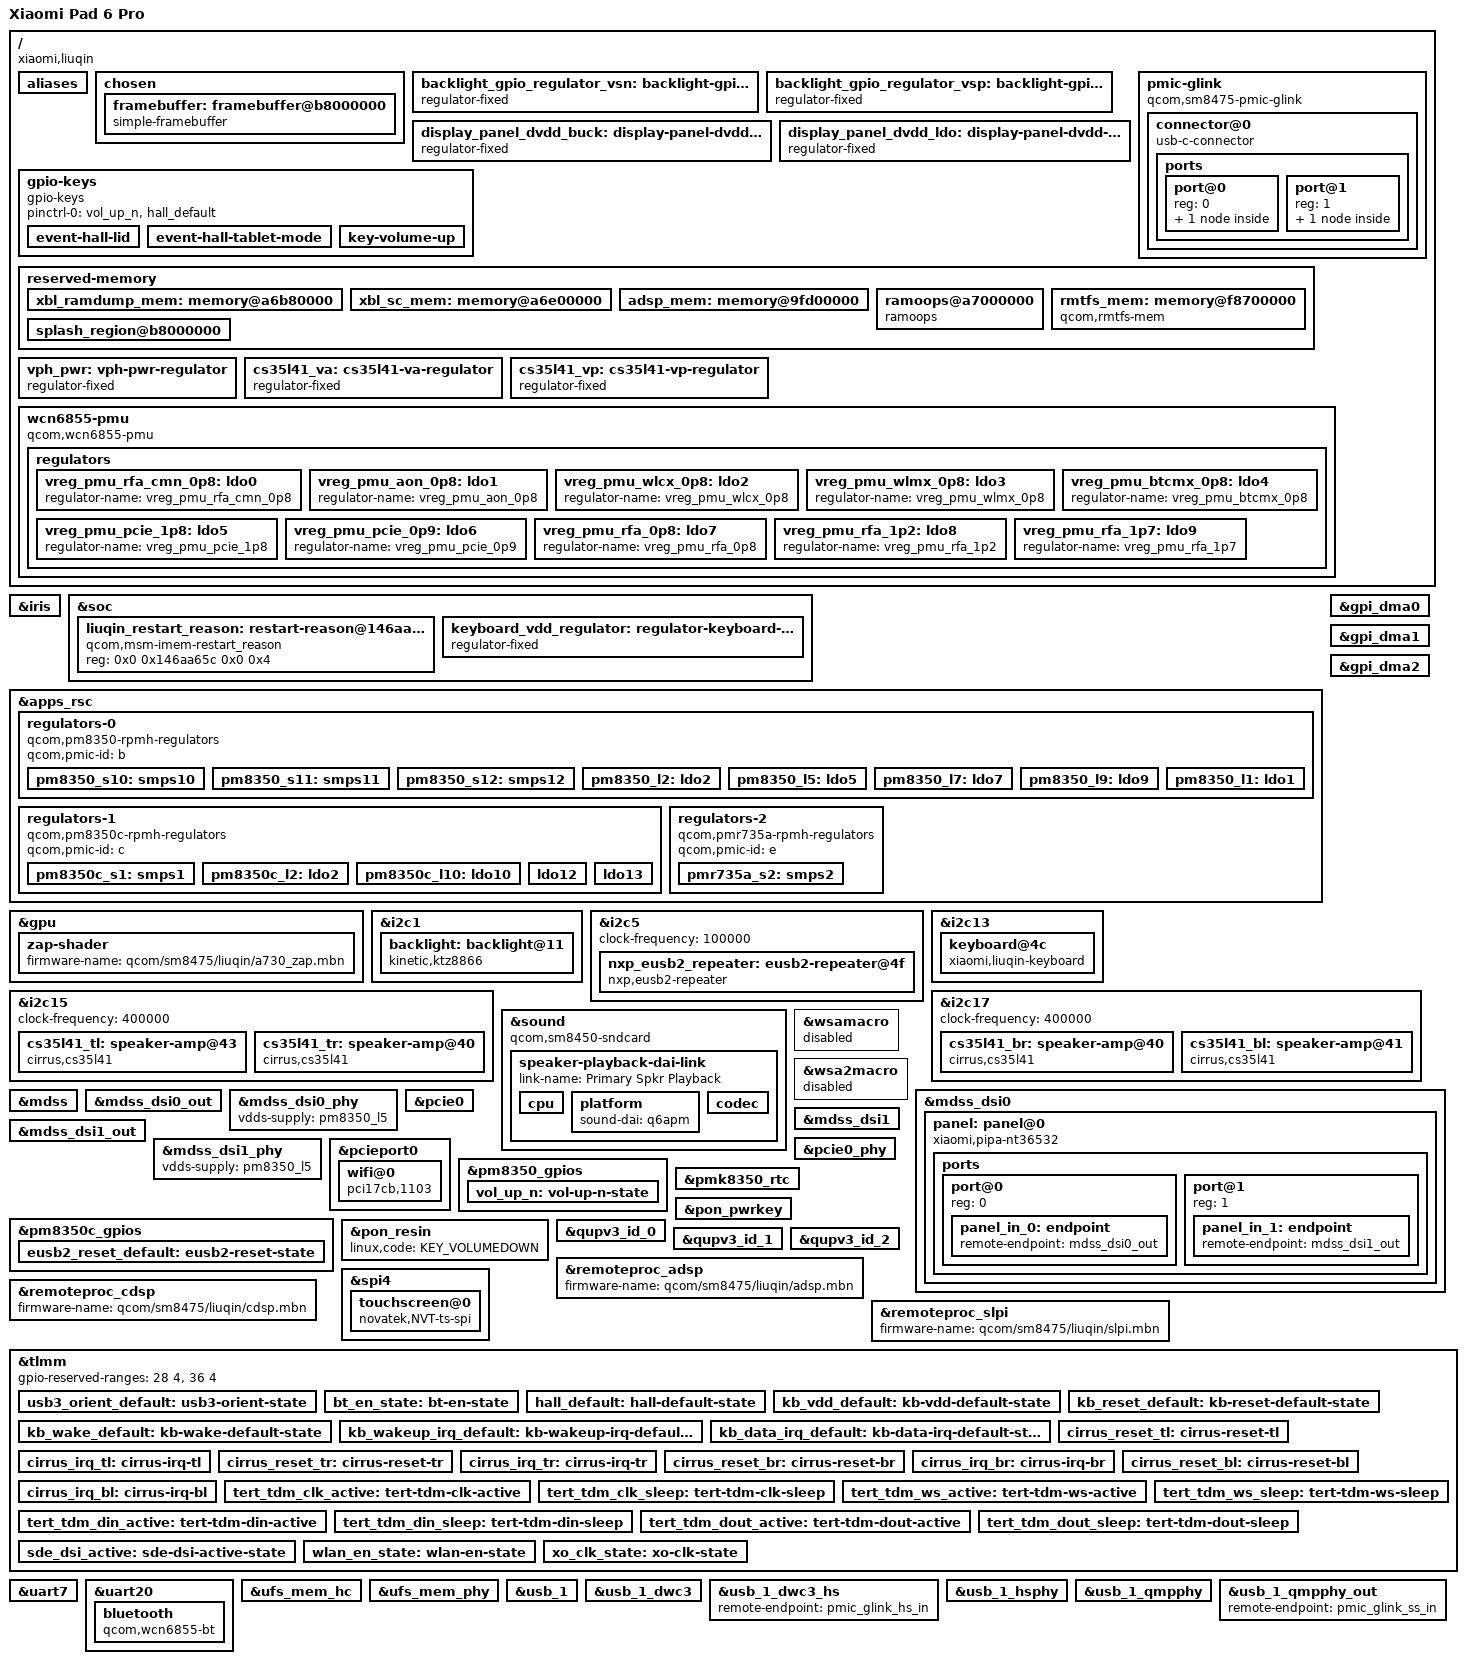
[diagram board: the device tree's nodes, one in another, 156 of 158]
// SPDX-License-Identifier: GPL-2.0-only
/dts-v1/;

#include <dt-bindings/input/input.h>
#include <dt-bindings/interrupt-controller/irq.h>
#include <dt-bindings/pinctrl/qcom,pmic-gpio.h>
#include <dt-bindings/regulator/qcom,rpmh-regulator.h>

#include "sm8475.dtsi"
#include "pm8350.dtsi"
#include "pm8350b.dtsi"
#include "pm8350c.dtsi"
#include "pm8450.dtsi"
#include "pmk8350.dtsi"
#include "pmr735a.dtsi"

/* The firmware memory map differs from the generic SM8450 layout. */
/delete-node/ &adsp_mem;
/delete-node/ &rmtfs_mem;
/delete-node/ &xbl_ramdump_mem;
/delete-node/ &xbl_sc_mem;

/ {
	model = "Xiaomi Pad 6 Pro";
	compatible = "xiaomi,liuqin", "qcom,sm8475";
	chassis-type = "tablet";

	aliases {
		hsuart0 = &uart20;
		serial0 = &uart7;
	};

	chosen {
		#address-cells = <2>;
		#size-cells = <2>;
		ranges;

		stdout-path = "serial0:115200n8";
		/*
		 * The bootloader appends its own command line to this property
		 * rather than replacing it, so the kernel only ever sees what is
		 * written here. Keep it in sync with the boot image header.
		 *
		 * The panel is the only channel on a retail tablet. earlycon=simplefb
		 * draws onto the framebuffer below from parse_early_param(), which is
		 * the only way to see a failure earlier than device_initcall, where
		 * the DRM log client can take over. Four parts are load-bearing and
		 * each one
		 * silently loses that window on its own:
		 *
		 *   earlycon=simplefb   - a bare "earlycon" never reaches the DT,
		 *                         CONFIG_ACPI_SPCR_TABLE claims it first.
		 *   keep_bootcon        - console_init() runs before every initcall
		 *                         and registers the VT console as CON_CONSDEV,
		 *                         at which point printk unregisters every
		 *                         CON_BOOT console unless this is set.
		 *   console=drm_log     - enables the late-registering DRM console;
		 *                         its first write is what commits the initial
		 *                         atomic modeset. console=tty0 follows it so
		 *                         /dev/console remains the VT for userspace.
		 *   initcall_blacklist= - stops simplefb binding, so fbcon never takes
		 *     simplefb_driver_init  the same framebuffer and the two consoles
		 *                         do not draw over each other. Costs nothing:
		 *                         if the boot gets that far we have USB.
		 * stdout-path is not used by either console -- it names the GENI debug
		 * UART, which is not brought out on a retail unit.
		 */
		bootargs = "earlycon=simplefb keep_bootcon console=drm_log console=tty0 initcall_blacklist=simplefb_driver_init initcall_debug ignore_loglevel clk_ignore_unused pd_ignore_unused rootwait mtdoops.dump_oops=1 hung_task_panic=1 softlockup_panic=1 panic=15";

		framebuffer: framebuffer@b8000000 {
			compatible = "simple-framebuffer";
			reg = <0x0 0xb8000000 0x0 0x2b00000>;
			width = <1800>;
			height = <2880>;
			stride = <(1800 * 4)>;
			format = "a8r8g8b8";

			clocks = <&gcc GCC_DISP_HF_AXI_CLK>;
		};
	};

	/*
	 * The panel and its backlight run off five rails. One is a PMIC LDO
	 * (iovdd, pm8350c_l2, wired at &mdss_dsi0/panel@0 below); the other four
	 * are load switches the SoC gates directly, which the vendor tree models
	 * as regulator-fixed with a TLMM gpio -- and so does this, node for node,
	 * following the stock device tree supplied by the bootloader:
	 *
	 *   display_gpio_regulator_dvdd_buck  :33115  gpio 2   1.3 V
	 *   display_gpio_regulator_dvdd_ldo   :33126  gpio 93  1.3 V
	 *   display_gpio_regulator_vsp        :33137  gpio 66  5.5 V, ramp 233 us
	 *   display_gpio_regulator_vsn        :33149  gpio 53  5.5 V, ramp 233 us
	 *
	 * vsp/vsn are not panel rails in the usual sense: gpio 66 and gpio 53 are
	 * the KTZ8866's own ENP and ENN pins (:12676-12677), i.e. the enables for
	 * its positive and negative LCD bias outputs. That is why they are
	 * consumed by backlight@11 as vddpos/vddneg rather than by the panel.
	 *
	 * regulator-always-on throughout, as on yudi: nothing here can be
	 * sequenced off safely while the bootloader's splash is still scanning
	 * out, and the panel driver's unprepare path would otherwise drop rails
	 * the earlycon framebuffer still depends on.
	 */
	backlight_gpio_regulator_vsn: backlight-gpio-reg-vsn {
		compatible = "regulator-fixed";
		regulator-name = "backlight_gpio_vsn";
		regulator-min-microvolt = <5500000>;
		regulator-max-microvolt = <5500000>;
		regulator-enable-ramp-delay = <233>;
		gpio = <&tlmm 53 GPIO_ACTIVE_HIGH>;
		enable-active-high;
		regulator-boot-on;
		regulator-always-on;
	};

	backlight_gpio_regulator_vsp: backlight-gpio-reg-vsp {
		compatible = "regulator-fixed";
		regulator-name = "backlight_gpio_vsp";
		regulator-min-microvolt = <5500000>;
		regulator-max-microvolt = <5500000>;
		regulator-enable-ramp-delay = <233>;
		gpio = <&tlmm 66 GPIO_ACTIVE_HIGH>;
		enable-active-high;
		regulator-boot-on;
		regulator-always-on;
	};

	display_panel_dvdd_buck: display-panel-dvdd-buck {
		compatible = "regulator-fixed";
		regulator-name = "display_panel_dvdd_buck";
		regulator-min-microvolt = <1300000>;
		regulator-max-microvolt = <1300000>;
		gpio = <&tlmm 2 GPIO_ACTIVE_HIGH>;
		enable-active-high;
		regulator-boot-on;
		regulator-always-on;
	};

	display_panel_dvdd_ldo: display-panel-dvdd-ldo {
		compatible = "regulator-fixed";
		regulator-name = "display_panel_dvdd_ldo";
		regulator-min-microvolt = <1300000>;
		regulator-max-microvolt = <1300000>;
		gpio = <&tlmm 93 GPIO_ACTIVE_HIGH>;
		enable-active-high;
		regulator-boot-on;
		regulator-always-on;
	};

	gpio-keys {
		compatible = "gpio-keys";

		pinctrl-0 = <&vol_up_n>, <&hall_default>;
		pinctrl-names = "default";

		/*
		 * Two hall switches, plain TLMM GPIOs (vendor hall_key/hall_key1,
		 * abl-final-fdt.dts gpio_keys): gpio10 closes with the folio lid,
		 * gpio23 signals tablet-mode.  SW_LID lets logind blank on close;
		 * SW_TABLET_MODE drives GNOME's on-screen-keyboard decision.  The
		 * nanosic keyboard MCU reads the same magnets separately; these
		 * switches do not depend on it.
		 */
		event-hall-lid {
			label = "Hall Lid";
			linux,input-type = <EV_SW>;
			linux,code = <SW_LID>;
			gpios = <&tlmm 10 GPIO_ACTIVE_LOW>;
			debounce-interval = <150>;
			wakeup-source;
		};

		event-hall-tablet-mode {
			label = "Hall Tablet Mode";
			linux,input-type = <EV_SW>;
			linux,code = <SW_TABLET_MODE>;
			/*
			 * GNOME semantics: SW_TABLET_MODE=1 means "no keyboard attached".
			 * This hall pin is pulled up when no magnet (keyboard/folio) is
			 * near, so active-high maps detached -> tablet mode and attached
			 * -> laptop mode -- the latter additionally gates GNOME's
			 * on-screen keyboard.
			 */
			gpios = <&tlmm 23 GPIO_ACTIVE_HIGH>;
			debounce-interval = <150>;
			wakeup-source;
		};

		key-volume-up {
			label = "Volume Up";
			linux,code = <KEY_VOLUMEUP>;
			gpios = <&pm8350_gpios 6 GPIO_ACTIVE_LOW>;
			debounce-interval = <15>;
			linux,can-disable;
			wakeup-source;
		};
	};

	/*
	 * The charger PD runs on ADSP and publishes PMIC_RTR_ADSP_APPS, exactly
	 * as the vendor FDT describes.  The connector is now wired through as
	 * well: pmic-glink UCSI reports the data role and CC orientation, the
	 * DWC3 follows it as an OTG dual-role port, and the QMP combo PHY takes
	 * the orientation for its lane swap (vendor routes the CC orientation
	 * line to TLMM gpio91).
	 */
	pmic-glink {
		compatible = "qcom,sm8475-pmic-glink",
			     "qcom,sm8450-pmic-glink",
			     "qcom,pmic-glink";
		#address-cells = <1>;
		#size-cells = <0>;

		orientation-gpios = <&tlmm 91 GPIO_ACTIVE_HIGH>;
		pinctrl-0 = <&usb3_orient_default>;
		pinctrl-names = "default";

		connector@0 {
			compatible = "usb-c-connector";
			reg = <0>;
			power-role = "dual";
			data-role = "dual";

			ports {
				#address-cells = <1>;
				#size-cells = <0>;

				port@0 {
					reg = <0>;

					pmic_glink_hs_in: endpoint {
						remote-endpoint = <&usb_1_dwc3_hs>;
					};
				};

				port@1 {
					reg = <1>;

					pmic_glink_ss_in: endpoint {
						remote-endpoint = <&usb_1_qmpphy_out>;
					};
				};
			};
		};
	};

	reserved-memory {
		xbl_ramdump_mem: memory@a6b80000 {
			reg = <0x0 0xa6b80000 0x0 0x280000>;
			no-map;
		};

		xbl_sc_mem: memory@a6e00000 {
			reg = <0x0 0xa6e00000 0x0 0x40000>;
			no-map;
		};

		adsp_mem: memory@9fd00000 {
			reg = <0x0 0x9fd00000 0x0 0x3100000>;
			no-map;
		};

		/*
		 * Zone sizes deliberately match the vendor firmware's own ramoops
		 * node, so the console zone lands at the same physical address and
		 * length in both kernels. That makes a failed boot here readable
		 * from the stock kernel's /sys/fs/pstore afterwards, which is the
		 * only post-mortem channel this board has: the debug UART is not
		 * accessible on a retail unit. pstore allocates dmesg, console then
		 * pmsg in that order, so any extra dmesg record zone would shift
		 * the console zone and break that compatibility.
		 */
		ramoops@a7000000 {
			compatible = "ramoops";
			reg = <0x0 0xa7000000 0x0 0x400000>;
			console-size = <0x200000>;
			pmsg-size = <0x200000>;
			no-map;
		};

		rmtfs_mem: memory@f8700000 {
			compatible = "qcom,rmtfs-mem";
			reg = <0x0 0xf8700000 0x0 0x280000>;
			no-map;

			qcom,client-id = <1>;
			qcom,vmid = <QCOM_SCM_VMID_MSS_MSA>;
		};

		splash_region@b8000000 {
			reg = <0x0 0xb8000000 0x0 0x2b00000>;
			no-map;
		};
	};

	vph_pwr: vph-pwr-regulator {
		compatible = "regulator-fixed";
		regulator-name = "vph_pwr";
		regulator-min-microvolt = <3700000>;
		regulator-max-microvolt = <3700000>;
		regulator-always-on;
		regulator-boot-on;
	};

	/*
	 * The four CS35L41 speaker amps have no VA-supply / VP-supply in the
	 * vendor tree the bootloader hands over (abl-final-fdt.dts:13410-13620).
	 * The rails are hard-wired. Mainline cs35l41_probe() still does a
	 * regulator_bulk_get() for "VA" and "VP" and will not probe without
	 * them; these always-on placeholders exist only to satisfy that API.
	 * They have no GPIO and do not gate hardware. Voltages are the
	 * datasheet-typical analog / battery rails, not a measured PMIC LDO.
	 */
	cs35l41_va: cs35l41-va-regulator {
		compatible = "regulator-fixed";
		regulator-name = "cs35l41_va";
		regulator-min-microvolt = <1800000>;
		regulator-max-microvolt = <1800000>;
		regulator-always-on;
		regulator-boot-on;
	};

	cs35l41_vp: cs35l41-vp-regulator {
		compatible = "regulator-fixed";
		regulator-name = "cs35l41_vp";
		regulator-min-microvolt = <3700000>;
		regulator-max-microvolt = <3700000>;
		regulator-always-on;
		regulator-boot-on;
	};

	/*
	 * Power sequencer for the QCA6490 combo chip. It owns the enable
	 * lines and the shared rails for both radios, so it has to exist
	 * before either the Bluetooth UART child below or a future WLAN
	 * endpoint on PCIe RC0 can be powered.
	 *
	 * GPIOs and supplies follow the stock device tree supplied by the
	 * bootloader to the vendor kernel.
	 * The vendor splits the same hardware across two nodes -- bt_qca6490
	 * at :1310 and qcom,cnss-qca6490 at :12525 -- which agree on every
	 * line: wlan-en gpio80 (0x50), bt-en gpio81 (0x51), sw-ctrl gpio82
	 * (0x52) and xo-clk gpio204 (0xcc), all against phandle 0x3c, which
	 * is pinctrl@f000000, i.e. TLMM (:1367).
	 */
	wcn6855-pmu {
		compatible = "qcom,wcn6855-pmu";

		pinctrl-0 = <&bt_en_state>, <&wlan_en_state>, <&xo_clk_state>;
		pinctrl-names = "default";

		wlan-enable-gpios = <&tlmm 80 GPIO_ACTIVE_HIGH>;
		bt-enable-gpios = <&tlmm 81 GPIO_ACTIVE_HIGH>;
		swctrl-gpios = <&tlmm 82 GPIO_ACTIVE_HIGH>;
		xo-clk-gpios = <&tlmm 204 GPIO_ACTIVE_HIGH>;

		vddio-supply = <&pm8350_s10>;
		vddaon-supply = <&pmr735a_s2>;
		vddpmu-supply = <&pm8350_s11>;
		vddpmumx-supply = <&pmr735a_s2>;
		vddpmucx-supply = <&pm8350_s11>;
		vddrfa0p95-supply = <&pm8350_s11>;
		vddrfa1p3-supply = <&pm8350_s12>;
		vddrfa1p9-supply = <&pm8350c_s1>;
		vddpcie1p3-supply = <&pm8350_s12>;
		vddpcie1p9-supply = <&pm8350c_s1>;

		regulators {
			vreg_pmu_rfa_cmn_0p8: ldo0 {
				regulator-name = "vreg_pmu_rfa_cmn_0p8";
			};

			vreg_pmu_aon_0p8: ldo1 {
				regulator-name = "vreg_pmu_aon_0p8";
			};

			vreg_pmu_wlcx_0p8: ldo2 {
				regulator-name = "vreg_pmu_wlcx_0p8";
			};

			vreg_pmu_wlmx_0p8: ldo3 {
				regulator-name = "vreg_pmu_wlmx_0p8";
			};

			vreg_pmu_btcmx_0p8: ldo4 {
				regulator-name = "vreg_pmu_btcmx_0p8";
			};

			vreg_pmu_pcie_1p8: ldo5 {
				regulator-name = "vreg_pmu_pcie_1p8";
			};

			vreg_pmu_pcie_0p9: ldo6 {
				regulator-name = "vreg_pmu_pcie_0p9";
			};

			vreg_pmu_rfa_0p8: ldo7 {
				regulator-name = "vreg_pmu_rfa_0p8";
			};

			vreg_pmu_rfa_1p2: ldo8 {
				regulator-name = "vreg_pmu_rfa_1p2";
			};

			vreg_pmu_rfa_1p7: ldo9 {
				regulator-name = "vreg_pmu_rfa_1p7";
			};
		};
	};
};

&iris {
	status = "okay";
};

/*
 * Power to the magnetic keyboard's pogo pins, gated by the vendor's vdd_pin
 * (abl-final-fdt.dts:13288). Nothing describes its voltage: the vendor tree
 * carries a bare GPIO with no rail behind it, and the bridge chip's supply is
 * generated on the folio side. startup-delay-us preserves the vendor's 2 ms
 * rail-to-reset delay.
 *
 * Keep the provider under the real simple-bus. ABL applies the vendor dtbo
 * after the boot image DTB and has already been observed rewriting or dropping
 * root-level additions, while children of /soc@0 survive in the live FDT.
 */
&soc {
	/*
	 * Xiaomi ABL consumes the Android restart reason at IMEM + 0x65c.
	 * The vendor FDT exposes the same 4-byte window below its msm-imem
	 * container; a direct /soc@0 child survives ABL's later overlay while
	 * root-level additions do not.
	 */
	liuqin_restart_reason: restart-reason@146aa65c {
		compatible = "qcom,msm-imem-restart_reason";
		reg = <0x0 0x146aa65c 0x0 0x4>;
	};

	keyboard_vdd_regulator: regulator-keyboard-vdd {
		compatible = "regulator-fixed";
		regulator-name = "keyboard_vdd";

		gpio = <&tlmm 62 GPIO_ACTIVE_HIGH>;
		enable-active-high;
		startup-delay-us = <2000>;

		pinctrl-0 = <&kb_vdd_default>;
		pinctrl-names = "default";
	};
};

&apps_rsc {
	regulators-0 {
		compatible = "qcom,pm8350-rpmh-regulators";
		qcom,pmic-id = "b";

		pm8350_s10: smps10 {
			regulator-name = "pm8350_s10";
			regulator-min-microvolt = <1800000>;
			regulator-max-microvolt = <1800000>;
		};

		pm8350_s11: smps11 {
			regulator-name = "pm8350_s11";
			regulator-min-microvolt = <382000>;
			regulator-max-microvolt = <1170000>;
		};

		pm8350_s12: smps12 {
			regulator-name = "pm8350_s12";
			regulator-min-microvolt = <1224000>;
			regulator-max-microvolt = <2040000>;
		};

		pm8350_l2: ldo2 {
			regulator-name = "pm8350_l2";
			regulator-min-microvolt = <2700000>;
			regulator-max-microvolt = <3300000>;
			regulator-initial-mode = <RPMH_REGULATOR_MODE_HPM>;
		};

		pm8350_l5: ldo5 {
			regulator-name = "pm8350_l5";
			regulator-min-microvolt = <720000>;
			regulator-max-microvolt = <958000>;
			regulator-initial-mode = <RPMH_REGULATOR_MODE_HPM>;
		};

		pm8350_l7: ldo7 {
			regulator-name = "pm8350_l7";
			regulator-min-microvolt = <2400000>;
			regulator-max-microvolt = <3544000>;
			regulator-initial-mode = <RPMH_REGULATOR_MODE_HPM>;
		};

		pm8350_l9: ldo9 {
			regulator-name = "pm8350_l9";
			regulator-min-microvolt = <1200000>;
			regulator-max-microvolt = <1304000>;
			regulator-initial-mode = <RPMH_REGULATOR_MODE_HPM>;
		};

		/*
		 * USB3 QMP combo PHY PLL rail. The vendor names L1B as the
		 * ssphy vdd-supply at 0.912 V (vendor FDT usb_qmp_dp_phy).
		 */
		pm8350_l1: ldo1 {
			regulator-name = "pm8350_l1";
			regulator-min-microvolt = <912000>;
			regulator-max-microvolt = <912000>;
			regulator-initial-mode = <RPMH_REGULATOR_MODE_HPM>;
		};
	};

	regulators-1 {
		compatible = "qcom,pm8350c-rpmh-regulators";
		qcom,pmic-id = "c";

		pm8350c_s1: smps1 {
			regulator-name = "pm8350c_s1";
			regulator-min-microvolt = <1800000>;
			regulator-max-microvolt = <2024000>;
			regulator-always-on;
		};

		/*
		 * The panel's iovdd. Range copied from the vendor's own
		 * regulator-pm8350c-l2 (abl-final-fdt.dts:6179-6187,
		 * phandle 0x301), which qcom,dsi-display-primary names as
		 * iovdd-supply at :32975.
		 */
		pm8350c_l2: ldo2 {
			regulator-name = "pm8350c_l2";
			regulator-min-microvolt = <1800000>;
			regulator-max-microvolt = <1980000>;
			regulator-initial-mode = <RPMH_REGULATOR_MODE_HPM>;
		};

		pm8350c_l10: ldo10 {
			regulator-name = "pm8350c_l10";
			regulator-min-microvolt = <1200000>;
			regulator-max-microvolt = <1304000>;
			regulator-initial-mode = <RPMH_REGULATOR_MODE_HPM>;
		};

		ldo12 {
			regulator-name = "pm8350c_l12";
			regulator-min-microvolt = <1800000>;
			regulator-max-microvolt = <1800000>;
			regulator-initial-mode = <RPMH_REGULATOR_MODE_HPM>;
			regulator-boot-on;
			regulator-always-on;
		};

		ldo13 {
			regulator-name = "pm8350c_l13";
			regulator-min-microvolt = <3304000>;
			regulator-max-microvolt = <3304000>;
			regulator-initial-mode = <RPMH_REGULATOR_MODE_HPM>;
			regulator-boot-on;
			regulator-always-on;
		};
	};

	regulators-2 {
		compatible = "qcom,pmr735a-rpmh-regulators";
		qcom,pmic-id = "e";

		pmr735a_s2: smps2 {
			regulator-name = "pmr735a_s2";
			regulator-min-microvolt = <500000>;
			regulator-max-microvolt = <1040000>;
			regulator-always-on;
		};
	};
};

&gpi_dma0 {
	status = "okay";
};

&gpi_dma1 {
	status = "okay";
};

&gpi_dma2 {
	status = "okay";
};

&gpu {
	status = "okay";

	zap-shader {
		firmware-name = "qcom/sm8475/liuqin/a730_zap.mbn";
	};
};

/*
 * The backlight is a Kinetic KTZ8866 at address 0x11 on QUPv3 wrapper 0's
 * second serial engine -- the vendor's i2c@984000 (abl-final-fdt.dts:12657),
 * which is what sm8450.dtsi:1364 calls i2c1. Address, enable line and the
 * ENP/ENN rails all come from the vendor's ktz8866@11 (:12674-12681).
 *
 * No clock-frequency: sm8450.dtsi does not set one, so i2c-qcom-geni falls
 * back to 100 kHz, which is what yudi runs this same chip on this same bus at.
 * The vendor node does not specify one either.
 */
&i2c1 {
	status = "okay";

	/*
	 * "kinetic,ktz8866", not ktz8866a. The fork's driver keys a two-chip
	 * interlock off the compatible: ktz8866a is driver_data 1 and
	 * ktz8866_probe() returns -EPROBE_DEFER for as long as no ktz8866b has
	 * registered (drivers/video/backlight/ktz8866.c:147). That pairing is a
	 * 14" yudi thing -- it carries two of these, on i2c1 and i2c5. This
	 * unit has exactly one (abl-final-fdt.dts:12674), so anything but the
	 * plain compatible would defer forever, and the panel, which waits on
	 * this device through drm_panel_of_backlight(), would defer with it.
	 *
	 * current-num-sinks = 5 follows sm8250-xiaomi-pipa.dts:519 and
	 * sm8250-xiaomi-elish-common.dtsi:585 rather than yudi: the vendor tree
	 * specifies no sink count at all, and pipa is the same 11" panel
	 * generation. Enabling a sink with no string on it is what the driver
	 * would do by default (all six, ktz8866.c:110-113).
	 */
	backlight: backlight@11 {
		compatible = "kinetic,ktz8866";
		reg = <0x11>;

		vddpos-supply = <&backlight_gpio_regulator_vsp>;
		vddneg-supply = <&backlight_gpio_regulator_vsn>;

		enable-gpios = <&tlmm 6 GPIO_ACTIVE_HIGH>;

		current-num-sinks = <5>;
		kinetic,current-ramp-delay-ms = <128>;
		kinetic,led-enable-ramp-delay-ms = <1>;
		kinetic,enable-lcd-bias;
	};
};

&i2c5 {
	clock-frequency = <100000>;
	status = "okay";

	nxp_eusb2_repeater: eusb2-repeater@4f {
		compatible = "nxp,eusb2-repeater";
		reg = <0x4f>;
		vdd18-supply = <&pm8350_s10>;
		vdd3-supply = <&pm8350_l2>;
		reset-gpios = <&pm8350c_gpios 7 GPIO_ACTIVE_HIGH>;
		pinctrl-0 = <&eusb2_reset_default>;
		pinctrl-names = "default";
		#phy-cells = <0>;

		qcom,param-override-seq = <0x40 0x06 0x00 0x07
					     0x63 0x08 0x03 0x0a>;
		qcom,param-override-seq-host = <0x40 0x06 0x21 0x07
						  0x64 0x08 0x03 0x0a>;
	};
};

/*
 * The magnetic keyboard folio's bridge chip, a Nanosic WN8030. The vendor tree
 * has it as nanosic@4c under i2c@a94000 (abl-final-fdt.dts:13263-13293), which
 * is sm8450.dtsi's i2c13 -- QUPv3 wrapper 1, SE 5. The pin state that .dtsi
 * already selects for it, qup_i2c13_data_clk, is gpio48/gpio49 at drive 2 with
 * a pull-up, matching the vendor's qupv3_se13_i2c_active (:3438) word for word.
 *
 * No clock-frequency, for the same reason as the amplifiers below: the vendor
 * node sets none, so the bus runs at i2c-qcom-geni's 100 kHz default.
 */
&i2c13 {
	status = "okay";

	keyboard@4c {
		compatible = "xiaomi,liuqin-keyboard", "nanosic,wn8030";
		reg = <0x4c>;

		/*
		 * Two lines out of the bridge:
		 *
		 *  "data"   gpio50. The vendor passes this pin's third DT cell,
		 *           0x6001, straight to request_threaded_irq() as flags
		 *           (nano_driver.c:67 -> nano_i2c.c:543), where it reads
		 *           as NO_SUSPEND | ONESHOT | TRIGGER_RISING. Rising is
		 *           what matters here; the source comment nearby claims
		 *           falling and is simply wrong.
		 *  "wakeup" gpio46, the vendor's status_pin: a rising edge while
		 *           the system is suspended. The I2C core claims this named
		 *           dedicated wake IRQ; hid-nanosic owns only the data IRQ.
		 */
		interrupts-extended = <&tlmm 50 IRQ_TYPE_EDGE_RISING>,
				      <&tlmm 46 IRQ_TYPE_EDGE_RISING>;
		interrupt-names = "data", "wakeup";

		vdd-supply = <&keyboard_vdd_regulator>;

		/* reset_pin gpio83, asserted low. */
		reset-gpios = <&tlmm 83 GPIO_ACTIVE_LOW>;

		/*
		 * sleep_pin gpio42: high keeps the bridge running, low lets it
		 * sleep. Named for what the line does, because the vendor's own
		 * Nanosic_GPIO_sleep(true) means wake up, not sleep.
		 */
		wake-gpios = <&tlmm 42 GPIO_ACTIVE_HIGH>;

		pinctrl-0 = <&kb_data_irq_default>, <&kb_wakeup_irq_default>,
			    <&kb_reset_default>, <&kb_wake_default>;
		pinctrl-names = "default";

		wakeup-source;

		/*
		 * Deliberately no hall-*-gpios. The vendor node lists
		 * hall_n_pin gpio10 and hall_s_pin gpio23, but those two are
		 * already claimed above as gpio-keys SW_LID / SW_TABLET_MODE,
		 * which is what logind and GNOME consume. A second consumer
		 * would take this node's probe down with -EBUSY, and would gain
		 * nothing: the vendor driver only forwarded those levels to a
		 * Xiaomi userspace daemon that does not exist here.
		 */
	};
};

/*
 * Speaker amplifiers. Four Cirrus CS35L41 parts, two per I2C controller, from
 * the tree the bootloader actually handed the vendor kernel:
 *
 *   i2c@880000 (sm8450.dtsi i2c15)  abl-final-fdt.dts:13393
 *     @43 TL  reset gpio1   irq gpio88   :13410-13433
 *     @40 TR  reset gpio3   irq gpio63   :13435-13458
 *   i2c@888000 (sm8450.dtsi i2c17)  :13556
 *     @40 BR  reset gpio92  irq gpio89   :13572-13595
 *     @41 BL  reset gpio87  irq gpio90   :13597-13620
 *
 * Boost 4000 mA / 1000 nH / 15 uF, asp-sdout-hiz 3, gpio2 = push-pull INTB
 * (src-select 4) are copied from those nodes. Vendor interrupt flags 0x2008
 * collapse to IRQ_TYPE_LEVEL_LOW, which is what INTB active-low is.
 *
 * The machine driver and tertiary TDM backend live in &sound below. Still no
 * speaker-protection firmware: DAPM PRE_PMU must fail closed. Do not play.
 *
 * Preserve the vendor driver's default 400 kHz explicitly. A 20300-byte
 * protection firmware block exceeds mainline's one-second timeout at 100 kHz.
 */
&i2c15 {
	clock-frequency = <400000>;
	status = "okay";

	cs35l41_tl: speaker-amp@43 {
		compatible = "cirrus,cs35l41";
		reg = <0x43>;
		#sound-dai-cells = <1>;
		sound-name-prefix = "TL";

		VA-supply = <&cs35l41_va>;
		VP-supply = <&cs35l41_vp>;

		reset-gpios = <&tlmm 1 GPIO_ACTIVE_HIGH>;
		interrupt-parent = <&tlmm>;
		interrupts = <88 IRQ_TYPE_LEVEL_LOW>;
		pinctrl-names = "default";
		pinctrl-0 = <&cirrus_reset_tl>, <&cirrus_irq_tl>;

		cirrus,boost-peak-milliamp = <4000>;
		cirrus,boost-ind-nanohenry = <1000>;
		cirrus,boost-cap-microfarad = <15>;
		cirrus,asp-sdout-hiz = <3>;
		cirrus,gpio2-src-select = <4>;
		cirrus,gpio2-output-enable;
	};

	cs35l41_tr: speaker-amp@40 {
		compatible = "cirrus,cs35l41";
		reg = <0x40>;
		#sound-dai-cells = <1>;
		sound-name-prefix = "TR";

		VA-supply = <&cs35l41_va>;
		VP-supply = <&cs35l41_vp>;

		reset-gpios = <&tlmm 3 GPIO_ACTIVE_HIGH>;
		interrupt-parent = <&tlmm>;
		interrupts = <63 IRQ_TYPE_LEVEL_LOW>;
		pinctrl-names = "default";
		pinctrl-0 = <&cirrus_reset_tr>, <&cirrus_irq_tr>;

		cirrus,boost-peak-milliamp = <4000>;
		cirrus,boost-ind-nanohenry = <1000>;
		cirrus,boost-cap-microfarad = <15>;
		cirrus,asp-sdout-hiz = <3>;
		cirrus,gpio2-src-select = <4>;
		cirrus,gpio2-output-enable;
	};
};

&i2c17 {
	clock-frequency = <400000>;
	status = "okay";

	cs35l41_br: speaker-amp@40 {
		compatible = "cirrus,cs35l41";
		reg = <0x40>;
		#sound-dai-cells = <1>;
		sound-name-prefix = "BR";

		VA-supply = <&cs35l41_va>;
		VP-supply = <&cs35l41_vp>;

		reset-gpios = <&tlmm 92 GPIO_ACTIVE_HIGH>;
		interrupt-parent = <&tlmm>;
		interrupts = <89 IRQ_TYPE_LEVEL_LOW>;
		pinctrl-names = "default";
		pinctrl-0 = <&cirrus_reset_br>, <&cirrus_irq_br>;

		cirrus,boost-peak-milliamp = <4000>;
		cirrus,boost-ind-nanohenry = <1000>;
		cirrus,boost-cap-microfarad = <15>;
		cirrus,asp-sdout-hiz = <3>;
		cirrus,gpio2-src-select = <4>;
		cirrus,gpio2-output-enable;
	};

	cs35l41_bl: speaker-amp@41 {
		compatible = "cirrus,cs35l41";
		reg = <0x41>;
		#sound-dai-cells = <1>;
		sound-name-prefix = "BL";

		VA-supply = <&cs35l41_va>;
		VP-supply = <&cs35l41_vp>;

		reset-gpios = <&tlmm 87 GPIO_ACTIVE_HIGH>;
		interrupt-parent = <&tlmm>;
		interrupts = <90 IRQ_TYPE_LEVEL_LOW>;
		pinctrl-names = "default";
		pinctrl-0 = <&cirrus_reset_bl>, <&cirrus_irq_bl>;

		cirrus,boost-peak-milliamp = <4000>;
		cirrus,boost-ind-nanohenry = <1000>;
		cirrus,boost-cap-microfarad = <15>;
		cirrus,asp-sdout-hiz = <3>;
		cirrus,gpio2-src-select = <4>;
		cirrus,gpio2-output-enable;
	};
};

/*
 * Speaker backend only. Vendor waipio-asoc-snd has qcom,wsa-max-devs = <0>
 * and disables the WSA SoundWire pin states (abl-final-fdt.dts:32346,
 * :32385-32404); tert_tdm_pinctrl is ok and tert_mi2s_pinctrl is disabled
 * (:32365-32383). Playback is four CS35L41s on tertiary TDM, not WSA883x.
 * Pins gpio121/122/123/124 as mi2s2_sck/data0/ws/data1 match that FDT
 * (:1795-1928) and cupid's TDM pinmux. Do not add WCD, WSA, or firmware-name.
 *
 * This is a DPCM backend: q6apm consumes the matching AudioReach topology
 * qcom/sm8450/Xiaomi-Pad-6-Pro-tplg.bin. The topology and the standard TDM
 * slot properties below form one atomic dependency; omitting either makes the
 * PCM unusable. DAPM must not reach DSP1 Preloader: the image has no wmfw.
 */
&sound {
	compatible = "qcom,sm8450-sndcard";
	model = "Xiaomi-Pad-6-Pro";

	pinctrl-names = "default", "sleep";
	pinctrl-0 = <&tert_tdm_clk_active>, <&tert_tdm_ws_active>,
		    <&tert_tdm_din_active>, <&tert_tdm_dout_active>;
	pinctrl-1 = <&tert_tdm_clk_sleep>, <&tert_tdm_ws_sleep>,
		    <&tert_tdm_din_sleep>, <&tert_tdm_dout_sleep>;

	speaker-playback-dai-link {
		link-name = "Primary Spkr Playback";

		cpu {
			sound-dai = <&q6apmbedai TERTIARY_TDM_RX_0>;
			/*
			 * The liuqin vendor speaker group is 48 kHz, four-channel,
			 * 24-bit with slots 0..3 active (backend_conf.xml and the
			 * cape resource manager both say mask 0xf).  S24_LE has a
			 * 32-bit physical container, and q6apm accepts 16 or 32-bit
			 * serial slots only, hence four 32-bit TDM slots.
			 */
			dai-tdm-slot-num = <4>;
			dai-tdm-slot-width = <32>;
			dai-tdm-slot-rx-mask = <1 1 1 1>;
		};

		platform {
			sound-dai = <&q6apm>;
		};

		codec {
			sound-dai = <&cs35l41_tl 0>, <&cs35l41_tr 0>,
				    <&cs35l41_br 0>, <&cs35l41_bl 0>;
		};
	};
};

&wsamacro {
	status = "disabled";
};

&wsa2macro {
	status = "disabled";
};

/*
 * Display. The panel is an 1800x2880 Novatek NT36532 driven at 120 Hz over two
 * bonded DSI links with DSC 1.1, 450x20 slices. Every number below is taken
 * from the m81_42_02_0b panel node in the device tree this unit's bootloader
 * hands the vendor kernel, abl-final-fdt.dts:26160-26294 -- never from
 * sources/sm8450-fdt/liuqin.dts, whose pretty-printer renders any integer that
 * happens to equal a phandle as a <&label> and silently corrupts exactly the
 * numbers that matter here.
 *
 * The timings live in the panel driver rather than in this file, and they are
 * verifiable: running the vendor's porches (2*(100,2,46) horizontal, 26/2/214
 * vertical) through dsi_host.c's own arithmetic -- compression-adjusted pclk,
 * bonded halving, byte clock -- reproduces the vendor's declared per-lane rate
 * of 1 007 032 320 Hz bit for bit. See docs/DISPLAY_RECON.zh-CN.md.
 *
 * Deliberately left alone: /chosen/bootargs, framebuffer@b8000000 and
 * splash_region. earlycon=simplefb is still the only channel that can show a
 * failure before device_initcall, and initcall_blacklist=simplefb_driver_init
 * keeps fbcon off that same memory. Once DRM comes up it registers its own
 * fb0, fbcon binds to it, and the earlycon simply goes blind -- which costs
 * nothing now that telnet and a full dmesg are available on this board.
 */
&mdss {
	status = "okay";
};

&mdss_dsi0 {
	vdda-supply = <&pm8350c_l10>;

	/*
	 * qcom,dual-dsi-mode, qcom,master-dsi and qcom,sync-dual-dsi are the
	 * three properties dsi_manager.c:47-63 reads to put the pair into
	 * bonded mode, where the DRM mode carries the full 1800 px width and
	 * each host drives half of it.
	 */
	qcom,dual-dsi-mode;
	qcom,master-dsi;
	qcom,sync-dual-dsi;

	status = "okay";

	/*
	 * Reuse pipa's description rather than adding a liuqin one. Every field
	 * of pipa_desc (drivers/gpu/drm/panel/panel-novatek-nt36532.c:442-461)
	 * matches this unit's m81_42_02_0b: mode, porches, 120 Hz, 450x20
	 * slices, 2 slices per link, 8 bpc, 8 bpp, block prediction, physical
	 * size. Its init sequence agrees with the vendor's 194-command blob in
	 * 183 places, including the one command that encodes this panel's
	 * porches, 3b 03 d8 1a 0a 0a 00, where 0xd8 is VBP+2 and 0x1a is VFP.
	 *
	 * reset-gpios is GPIO_ACTIVE_HIGH and that is not a copy of yudi.
	 * pipa_reset() (:48-57) drives the line 0,1,0,1 with 12 ms between each
	 * step and *ends on 1*, whereas yudi_reset() (:59-67) ends on 0. Only
	 * one polarity makes each of them leave the panel out of reset, and for
	 * pipa_reset() that is active-high: it then produces low, high, low,
	 * high, which is the vendor's own reset waveform
	 * qcom,mdss-dsi-reset-sequence = <0 10 1 3 0 3 1 15> (:26205) in shape,
	 * ending deasserted, differing only in the dwell times. With
	 * GPIO_ACTIVE_LOW the same helper inverts to high, low, high, low and
	 * leaves NT36532 nRESET asserted for the whole init sequence and PPS --
	 * every DSI write would still report success and the panel would stay
	 * black with nothing in dmesg to explain it.
	 *
	 * No te-gpios: this is video mode, so there is no tear-effect
	 * handshake. The vendor wires TE to gpio86 with the mdp_vsync function
	 * (:32985, sde_te_active) for its command-mode paths; mainline's msm
	 * DSI has no consumer for it here.
	 */
	panel: panel@0 {
		compatible = "xiaomi,pipa-nt36532";
		reg = <0>;

		vddio-supply = <&pm8350c_l2>;
		dvddbuck-supply = <&display_panel_dvdd_buck>;
		dvddldo-supply = <&display_panel_dvdd_ldo>;

		reset-gpios = <&tlmm 0 GPIO_ACTIVE_HIGH>;
		backlight = <&backlight>;

		pinctrl-0 = <&sde_dsi_active>;
		pinctrl-names = "default";

		ports {
			#address-cells = <1>;
			#size-cells = <0>;

			port@0 {
				reg = <0>;

				panel_in_0: endpoint {
					remote-endpoint = <&mdss_dsi0_out>;
				};
			};

			port@1 {
				reg = <1>;

				panel_in_1: endpoint {
					remote-endpoint = <&mdss_dsi1_out>;
				};
			};
		};
	};
};

&mdss_dsi0_out {
	remote-endpoint = <&panel_in_0>;
	data-lanes = <0 1 2 3>;
};

&mdss_dsi0_phy {
	vdds-supply = <&pm8350_l5>;

	status = "okay";
};

&mdss_dsi1 {
	vdda-supply = <&pm8350c_l10>;

	qcom,dual-dsi-mode;
	qcom,sync-dual-dsi;

	/*
	 * The second link's byte and pixel clocks are sourced from the *first*
	 * PHY's PLL, which is what keeps the two halves of the panel in step.
	 * This overrides the self-referencing parents sm8450.dtsi:3624-3626
	 * gives mdss_dsi1.
	 */
	assigned-clock-parents = <&mdss_dsi0_phy 0>, <&mdss_dsi0_phy 1>;

	status = "okay";
};

&mdss_dsi1_out {
	remote-endpoint = <&panel_in_1>;
	data-lanes = <0 1 2 3>;
};

&mdss_dsi1_phy {
	vdds-supply = <&pm8350_l5>;

	status = "okay";
};

/*
 * QCA6490 WLAN on PCIe RC0. The wifi child exists before enumeration so
 * pci-pwrctrl-pwrseq can claim the WCN6855 PMU's "wlan" target, raise gpio80
 * and the shared rails, and only then release the host bridge to scan the bus.
 * PCI pwrctrl is selected by ATH11K_PCI, so that dependency chain is built in;
 * E20 still ends when PCI core sees 17cb:1103 because WLAN runtime firmware is
 * deliberately absent and the driver must stop before firmware acceptance.
 */
&pcie0 {
	status = "okay";
};

&pcieport0 {
	wifi@0 {
		compatible = "pci17cb,1103";
		reg = <0x10000 0x0 0x0 0x0 0x0>;

		vddrfacmn-supply = <&vreg_pmu_rfa_cmn_0p8>;
		vddaon-supply = <&vreg_pmu_aon_0p8>;
		vddwlcx-supply = <&vreg_pmu_wlcx_0p8>;
		vddwlmx-supply = <&vreg_pmu_wlmx_0p8>;
		vddpcie1p8-supply = <&vreg_pmu_pcie_1p8>;
		vddpcie0p9-supply = <&vreg_pmu_pcie_0p9>;
		vddrfa0p8-supply = <&vreg_pmu_rfa_0p8>;
		vddrfa1p2-supply = <&vreg_pmu_rfa_1p2>;
		vddrfa1p8-supply = <&vreg_pmu_rfa_1p7>;
	};
};

&pcie0_phy {
	vdda-phy-supply = <&pm8350_l5>;
	vdda-pll-supply = <&pm8350c_l10>;

	status = "okay";
};

&pm8350_gpios {
	vol_up_n: vol-up-n-state {
		pins = "gpio6";
		function = PMIC_GPIO_FUNC_NORMAL;
		power-source = <1>;
		input-enable;
		bias-pull-up;
	};
};

&pm8350c_gpios {
	eusb2_reset_default: eusb2-reset-state {
		pins = "gpio7";
		function = PMIC_GPIO_FUNC_NORMAL;
		power-source = <1>;
		input-enable;
		output-enable;
		bias-disable;
		qcom,drive-strength = <PMIC_GPIO_STRENGTH_MED>;
	};
};

&pmk8350_rtc {
	/*
	 * Disabled upstream because not every SM8450-family board wires the RTC
	 * battery, so enabling it is a per-board statement. Without it the kernel
	 * has no real-time clock at all: it starts from the epoch and userspace
	 * shows whatever systemd can salvage from filesystem timestamps -- this
	 * tablet was reporting April while the host said August. On a desktop
	 * that is not cosmetic; TLS validation, apt metadata freshness and every
	 * log timestamp read from it.
	 */
	status = "okay";
};

&pon_pwrkey {
	status = "okay";
};

&pon_resin {
	linux,code = <KEY_VOLUMEDOWN>;
	status = "okay";
};

&qupv3_id_0 {
	status = "okay";
};

&qupv3_id_1 {
	status = "okay";
};

&qupv3_id_2 {
	status = "okay";
};

&remoteproc_adsp {
	firmware-name = "qcom/sm8475/liuqin/adsp.mbn";
	status = "okay";
};

&remoteproc_cdsp {
	firmware-name = "qcom/sm8475/liuqin/cdsp.mbn";
	status = "okay";
};

&remoteproc_slpi {
	firmware-name = "qcom/sm8475/liuqin/slpi.mbn";
	status = "okay";
};

/*
 * The touchscreen is a Novatek NT36532 on chip select 0 of QUPv3 wrapper 0's
 * fifth serial engine. Frequency, chip select and interrupt line are taken from
 * the device tree the vendor bootloader hands the vendor kernel on this exact
 * unit, captured during the E4 boot:
 * abl-final-fdt.dts:12799-12835, node spi@990000/touchscreen@0.
 *
 * No supply here on purpose: the vendor node has none either. The controller is
 * fed from the panel's rails, which is also why it can be brought up before the
 * display is.
 */
&spi4 {
	status = "okay";

	touchscreen@0 {
		compatible = "novatek,NVT-ts-spi";
		reg = <0>;

		spi-max-frequency = <9600000>;

		/*
		 * The trigger type is fixed in the driver (INT_TRIGGER_TYPE),
		 * which requests the interrupt from gpio_to_irq() rather than
		 * from this specifier, so this cell is documentation.
		 */
		novatek,irq-gpio = <&tlmm 21 IRQ_TYPE_EDGE_RISING>;

		/*
		 * Software reset register of the NT36532. The vendor tree does
		 * not carry this property -- its driver has the address
		 * compiled in -- but nvt_parse_dt() treats it as mandatory and
		 * fails probe without it. The value is the one the mainline
		 * driver's own NT36532 register table holds, and matches yudi,
		 * which has the same touch controller.
		 */
		novatek,swrst-n8-addr = <0x1fb43e>;

		novatek,pen-support;

		firmware-name = "novatek/liuqin/novatek_nt36532_m81_fw_csot.bin";

		/*
		 * The NT36532 is a TDDI die shared with the display. The DRM
		 * panel prepare sequence resets it and discards the RAM-loaded
		 * touch firmware, so the touch driver must follow the panel and
		 * download the firmware again after every prepare (E22 finding:
		 * touch worked in E12/E13 only because no display driver
		 * existed yet to reset the die).
		 */
		panel = <&panel>;
	};
};

&tlmm {
	gpio-reserved-ranges = <28 4>, <36 4>;
	status = "okay";

	/* Type-C CC orientation line into the QMP lane-swap decision. */
	usb3_orient_default: usb3-orient-state {
		pins = "gpio91";
		function = "gpio";
		bias-disable;
		input-enable;
	};

	/*
	 * The QCA6490 enable lines come up deasserted and are raised by the
	 * power sequencer when a radio is actually claimed. Levels, direction
	 * and bias match the vendor's own deasserted states -- bt_en_sleep
	 * (abl-final-fdt.dts:2570) and cnss_wlan_en_sleep (:4426) -- which is
	 * what the vendor's Bluetooth node uses as its default. The drive
	 * strength is 16 rather than the 2 those two states carry, because
	 * that is what the vendor selects in cnss_wlan_en_active (:4410) for
	 * the moment the line is actually driven, and it matches
	 * sm8450-hdk.dts, the mainline reference for this PMU.
	 */
	bt_en_state: bt-en-state {
		pins = "gpio81";
		function = "gpio";
		drive-strength = <16>;
		output-low;
		bias-pull-down;
	};

	/* Vendor xiaomi_hall_default: input, pull-up, drive 2. */
	hall_default: hall-default-state {
		pins = "gpio10", "gpio23";
		function = "gpio";
		drive-strength = <2>;
		input-enable;
		bias-pull-up;
	};

	/*
	 * The rest of the vendor's nanosic_keyboard_mcu group
	 * (abl-final-fdt.dts:5284-5331), split by function because the pins
	 * belong to two different consumers here -- gpio62 to the regulator,
	 * the other three to the bridge node. Drive strength and bias are the
	 * vendor's: xiaomi_keyboard_default puts gpio46, gpio83 and gpio62
	 * together at drive 2 with bias disabled, xiaomi_keyboard_sleep_default
	 * gives gpio42 a pull-down.
	 *
	 * gpio10 and gpio23 came out of that same vendor group and are
	 * described above as hall_default, owned by gpio-keys. They are not
	 * part of this set.
	 */
	kb_vdd_default: kb-vdd-default-state {
		pins = "gpio62";
		function = "gpio";
		drive-strength = <2>;
		bias-disable;
	};

	kb_reset_default: kb-reset-default-state {
		pins = "gpio83";
		function = "gpio";
		drive-strength = <2>;
		bias-disable;
	};

	kb_wake_default: kb-wake-default-state {
		pins = "gpio42";
		function = "gpio";
		drive-strength = <2>;
		bias-pull-down;
	};

	/* The vendor group leaves this an output-capable pin; it is an input. */
	kb_wakeup_irq_default: kb-wakeup-irq-default-state {
		pins = "gpio46";
		function = "gpio";
		drive-strength = <2>;
		bias-disable;
	};

	/*
	 * The vendor tree configures no pin state at all for gpio50 and relies
	 * on its driver calling gpio_direction_input(). This one is ours. The
	 * bridge drives the line push-pull, so it needs no bias.
	 */
	kb_data_irq_default: kb-data-irq-default-state {
		pins = "gpio50";
		function = "gpio";
		drive-strength = <2>;
		bias-disable;
	};

	/*
	 * CS35L41 reset and INTB pins. Drive 16 / bias-disable / output-high
	 * on reset and drive 2 / input-enable / pull-up on IRQ are the vendor
	 * cirrus_reset_default_* and cirrus_irq_default_* states at
	 * abl-final-fdt.dts:5185-5281.
	 */
	cirrus_reset_tl: cirrus-reset-tl {
		pins = "gpio1";
		function = "gpio";
		drive-strength = <16>;
		bias-disable;
		output-high;
	};

	cirrus_irq_tl: cirrus-irq-tl {
		pins = "gpio88";
		function = "gpio";
		drive-strength = <2>;
		input-enable;
		bias-pull-up;
	};

	cirrus_reset_tr: cirrus-reset-tr {
		pins = "gpio3";
		function = "gpio";
		drive-strength = <16>;
		bias-disable;
		output-high;
	};

	cirrus_irq_tr: cirrus-irq-tr {
		pins = "gpio63";
		function = "gpio";
		drive-strength = <2>;
		input-enable;
		bias-pull-up;
	};

	cirrus_reset_br: cirrus-reset-br {
		pins = "gpio92";
		function = "gpio";
		drive-strength = <16>;
		bias-disable;
		output-high;
	};

	cirrus_irq_br: cirrus-irq-br {
		pins = "gpio89";
		function = "gpio";
		drive-strength = <2>;
		input-enable;
		bias-pull-up;
	};

	cirrus_reset_bl: cirrus-reset-bl {
		pins = "gpio87";
		function = "gpio";
		drive-strength = <16>;
		bias-disable;
		output-high;
	};

	cirrus_irq_bl: cirrus-irq-bl {
		pins = "gpio90";
		function = "gpio";
		drive-strength = <2>;
		input-enable;
		bias-pull-up;
	};

	/*
	 * Tertiary TDM to the CS35L41s. Function, pins and drive come from
	 * abl-final-fdt.dts:1795-1928; sleep states are gpio + pull-down.
	 */
	tert_tdm_clk_active: tert-tdm-clk-active {
		pins = "gpio121";
		function = "mi2s2_sck";
		drive-strength = <8>;
		bias-disable;
		output-high;
	};

	tert_tdm_clk_sleep: tert-tdm-clk-sleep {
		pins = "gpio121";
		function = "gpio";
		drive-strength = <2>;
		bias-pull-down;
		input-enable;
	};

	tert_tdm_ws_active: tert-tdm-ws-active {
		pins = "gpio123";
		function = "mi2s2_ws";
		drive-strength = <8>;
		bias-disable;
		output-high;
	};

	tert_tdm_ws_sleep: tert-tdm-ws-sleep {
		pins = "gpio123";
		function = "gpio";
		drive-strength = <2>;
		bias-pull-down;
		input-enable;
	};

	tert_tdm_din_active: tert-tdm-din-active {
		pins = "gpio122";
		function = "mi2s2_data0";
		drive-strength = <8>;
		bias-disable;
	};

	tert_tdm_din_sleep: tert-tdm-din-sleep {
		pins = "gpio122";
		function = "gpio";
		drive-strength = <2>;
		bias-pull-down;
		input-enable;
	};

	tert_tdm_dout_active: tert-tdm-dout-active {
		pins = "gpio124";
		function = "mi2s2_data1";
		drive-strength = <8>;
		bias-disable;
	};

	tert_tdm_dout_sleep: tert-tdm-dout-sleep {
		pins = "gpio124";
		function = "gpio";
		drive-strength = <2>;
		bias-pull-down;
		input-enable;
	};

	/*
	 * The panel reset line. Function, drive strength and bias are the
	 * vendor's own sde_dsi_active (abl-final-fdt.dts:5527-5539); its
	 * counterpart sde_dsi_suspend, which pulls gpio0 down at drive strength
	 * 2, is not described because nothing here ever selects a suspend
	 * state for the panel.
	 */
	sde_dsi_active: sde-dsi-active-state {
		pins = "gpio0";
		function = "gpio";
		drive-strength = <8>;
		bias-disable;
	};

	wlan_en_state: wlan-en-state {
		pins = "gpio80";
		function = "gpio";
		drive-strength = <16>;
		output-low;
		bias-pull-down;
	};

	/*
	 * The vendor tree names gpio204 as qcom,xo-clk-gpio in both QCA6490
	 * nodes but configures no pin state for it, so this one follows
	 * sm8450-hdk.dts to give it a defined level before the sequencer
	 * pulses it.
	 */
	xo_clk_state: xo-clk-state {
		pins = "gpio204";
		function = "gpio";
		drive-strength = <16>;
		output-low;
		bias-pull-down;
	};
};

&uart7 {
	status = "okay";
};

/*
 * Bluetooth. The QCA6490's HCI transport is a 4-wire UART on QUPv3
 * wrapper 2's sixth serial engine, which the vendor tree describes at
 * abl-final-fdt.dts:13795 as qcom,qup_uart@894000 -- the same 0x894000
 * that sm8450.dtsi calls uart20. Pins are inherited from that .dtsi's
 * qup_uart20_default, whose cts/rts/tx/rx are gpio76/77/78/79, matching
 * the vendor's qupv3_se20_4uart_pins (:4148) pin for pin; that node's
 * wakeup interrupt on gpio79 independently confirms which end is rx.
 * Do not copy sm8450-hdk.dts's uart20_default override here: it labels
 * gpio78 rx and gpio79 tx, the other way round from both of those.
 */
&uart20 {
	status = "okay";

	bluetooth {
		compatible = "qcom,wcn6855-bt";

		vddrfacmn-supply = <&vreg_pmu_rfa_cmn_0p8>;
		vddaon-supply = <&vreg_pmu_aon_0p8>;
		vddwlcx-supply = <&vreg_pmu_wlcx_0p8>;
		vddwlmx-supply = <&vreg_pmu_wlmx_0p8>;
		vddbtcmx-supply = <&vreg_pmu_btcmx_0p8>;
		vddrfa0p8-supply = <&vreg_pmu_rfa_0p8>;
		vddrfa1p2-supply = <&vreg_pmu_rfa_1p2>;
		vddrfa1p8-supply = <&vreg_pmu_rfa_1p7>;

		max-speed = <3200000>;
	};
};

&ufs_mem_hc {
	reset-gpios = <&tlmm 210 GPIO_ACTIVE_LOW>;

	vcc-supply = <&pm8350_l7>;
	vcc-max-microamp = <1100000>;
	vccq-supply = <&pm8350_l9>;
	vccq-max-microamp = <1200000>;

	status = "okay";
};

&ufs_mem_phy {
	vdda-phy-supply = <&pm8350_l5>;
	vdda-pll-supply = <&pm8350c_l10>;

	status = "okay";
};

&usb_1 {
	/* select-utmi-as-pipe-clk removed: it waives the QMP pipe clock and is
	 * only valid for USB2-only operation. */
	status = "okay";
};

&usb_1_dwc3 {
	dr_mode = "otg";
	usb-role-switch;
	maximum-speed = "super-speed";
	phys = <&usb_1_hsphy>, <&usb_1_qmpphy QMP_USB43DP_USB3_PHY>;
	phy-names = "usb2-phy", "usb3-phy";
};

&usb_1_dwc3_hs {
	remote-endpoint = <&pmic_glink_hs_in>;
};

&usb_1_hsphy {
	vdd-supply = <&pm8350_l5>;
	vdda12-supply = <&pm8350c_l10>;
	phys = <&nxp_eusb2_repeater>;

	status = "okay";
};

&usb_1_qmpphy {
	status = "okay";

	vdda-phy-supply = <&pm8350c_l10>;
	vdda-pll-supply = <&pm8350_l1>;
};

&usb_1_qmpphy_out {
	remote-endpoint = <&pmic_glink_ss_in>;
};
